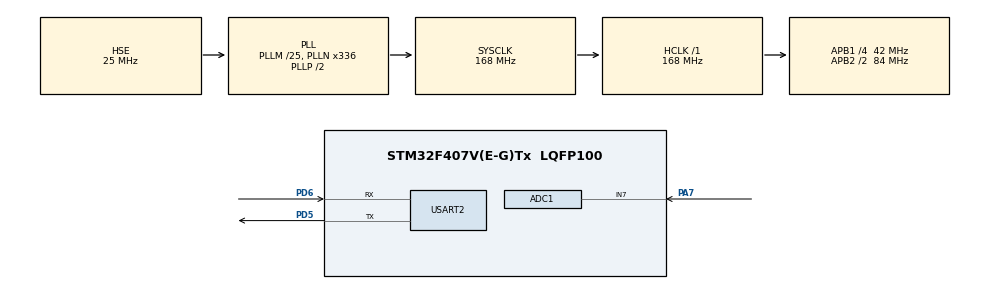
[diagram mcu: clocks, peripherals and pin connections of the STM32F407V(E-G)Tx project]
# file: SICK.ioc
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ADC1.Channel-3\#ChannelRegularConversion=ADC_CHANNEL_7
ADC1.ContinuousConvMode=ENABLE
ADC1.NbrOfConversionFlag=1
ADC1.Rank-3\#ChannelRegularConversion=1
ADC1.SamplingTime-3\#ChannelRegularConversion=ADC_SAMPLETIME_3CYCLES
ADC1.ScanConvMode=ENABLE
ADC1.master=1
Dma.ADC1.0.Direction=DMA_PERIPH_TO_MEMORY
Dma.ADC1.0.FIFOMode=DMA_FIFOMODE_DISABLE
Dma.ADC1.0.Instance=DMA2_Stream0
Dma.ADC1.0.MemDataAlignment=DMA_MDATAALIGN_WORD
Dma.ADC1.0.MemInc=DMA_MINC_ENABLE
Dma.ADC1.0.Mode=DMA_CIRCULAR
Dma.ADC1.0.PeriphDataAlignment=DMA_PDATAALIGN_WORD
Dma.ADC1.0.PeriphInc=DMA_PINC_DISABLE
Dma.ADC1.0.Priority=DMA_PRIORITY_LOW
Dma.Request0=ADC1
Mcu.Family=STM32F4
Mcu.Name=STM32F407V(E-G)Tx
Mcu.Package=LQFP100
NVIC.DMA2_Stream0_IRQn=true\:0\:0\:false\:false\:true\:false\:true\:true
NVIC.PriorityGroup=NVIC_PRIORITYGROUP_4
PA7.Signal=ADCx_IN7
PD5.Mode=Asynchronous
PD5.Signal=USART2_TX
PD6.Mode=Asynchronous
PD6.Signal=USART2_RX
PH0-OSC_IN.Mode=HSE-External-Oscillator
PH0-OSC_IN.Signal=RCC_OSC_IN
PH1-OSC_OUT.Mode=HSE-External-Oscillator
PH1-OSC_OUT.Signal=RCC_OSC_OUT
ProjectManager.HeapSize=0x200
ProjectManager.StackSize=0x400
ProjectManager.TargetToolchain=Makefile
RCC.48MHZClocksFreq_Value=48000000
RCC.AHBFreq_Value=168000000
RCC.APB1CLKDivider=RCC_HCLK_DIV4
RCC.APB1Freq_Value=42000000
RCC.APB1TimFreq_Value=84000000
RCC.APB2CLKDivider=RCC_HCLK_DIV2
RCC.APB2Freq_Value=84000000
RCC.APB2TimFreq_Value=168000000
RCC.CortexFreq_Value=168000000
RCC.HCLKFreq_Value=168000000
RCC.HSE_VALUE=25000000
RCC.HSI_VALUE=16000000
RCC.LSE_VALUE=32768
RCC.PLLM=25
RCC.PLLN=336
RCC.PLLQ=7
RCC.PLLSourceVirtual=RCC_PLLSOURCE_HSE
RCC.SYSCLKFreq_VALUE=168000000
RCC.SYSCLKSource=RCC_SYSCLKSOURCE_PLLCLK
RCC.VCOOutputFreq_Value=336000000
SH.ADCx_IN7.0=ADC1_IN7,IN7
USART2.VirtualMode=VM_ASYNC
board=custom

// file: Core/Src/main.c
/* USER CODE BEGIN Header */
/**
 ******************************************************************************
 * @file           : main.c
 * @brief          : Main program body
 ******************************************************************************
 * @attention
 *
 * Copyright (c) 2025 STMicroelectronics.
 * All rights reserved.
 *
 * This software is licensed under terms that can be found in the LICENSE file
 * in the root directory of this software component.
 * If no LICENSE file comes with this software, it is provided AS-IS.
 *
 ******************************************************************************
 */
/* USER CODE END Header */
#include "main.h"
#include "adc.h"
#include "dma.h"
#include "stm32f4xx_hal_uart.h"
#include "usart.h"
#include "gpio.h"

/* USER CODE BEGIN Includes */
#include <stdio.h>
/* USER CODE END Includes */

/* USER CODE BEGIN PV */
uint32_t ADC_BUFFER[1];
/* USER CODE END PV */

void SystemClock_Config(void);

/* USER CODE BEGIN 0 */
int _write(int file, char *data, int len)
{
  for (int i = 0; i < len; ++i)
  {
    ITM_SendChar(data[i]);
  }
  return len;
}

void HAL_ADC_ConvCpltCallback(ADC_HandleTypeDef *hadc) {
  for (int i = 0; i < 1; i++)
		HAL_UART_Transmit(&huart2, (uint8_t *)ADC_BUFFER, sizeof(ADC_BUFFER[i]), 1);
}
/* USER CODE END 0 */

int main(void)
{

  /* MCU Configuration--------------------------------------------------------*/

  /* Reset of all peripherals, Initializes the Flash interface and the Systick. */
  HAL_Init();

  /* Configure the system clock */
  SystemClock_Config();

  /* Initialize all configured peripherals */
  MX_GPIO_Init();
  MX_DMA_Init();
  MX_ADC1_Init();
  MX_USART2_UART_Init();

  /* Infinite loop */
  /* USER CODE BEGIN WHILE */
  while (1) {
		HAL_ADC_Start_DMA(&hadc1, ADC_BUFFER, 1);
    HAL_Delay(40);
    /* USER CODE END WHILE */

  }
}

void SystemClock_Config(void)
{
  RCC_OscInitTypeDef RCC_OscInitStruct = {0};
  RCC_ClkInitTypeDef RCC_ClkInitStruct = {0};

  /** Configure the main internal regulator output voltage
  */
  __HAL_RCC_PWR_CLK_ENABLE();
  __HAL_PWR_VOLTAGESCALING_CONFIG(PWR_REGULATOR_VOLTAGE_SCALE1);

  /** Initializes the RCC Oscillators according to the specified parameters
  * in the RCC_OscInitTypeDef structure.
  */
  RCC_OscInitStruct.OscillatorType = RCC_OSCILLATORTYPE_HSE;
  RCC_OscInitStruct.HSEState = RCC_HSE_ON;
  RCC_OscInitStruct.PLL.PLLState = RCC_PLL_ON;
  RCC_OscInitStruct.PLL.PLLSource = RCC_PLLSOURCE_HSE;
  RCC_OscInitStruct.PLL.PLLM = 25;
  RCC_OscInitStruct.PLL.PLLN = 336;
  RCC_OscInitStruct.PLL.PLLP = RCC_PLLP_DIV2;
  RCC_OscInitStruct.PLL.PLLQ = 7;
  if (HAL_RCC_OscConfig(&RCC_OscInitStruct) != HAL_OK)
  {
    Error_Handler();
  }

  /** Initializes the CPU, AHB and APB buses clocks
  */
  RCC_ClkInitStruct.ClockType = RCC_CLOCKTYPE_HCLK|RCC_CLOCKTYPE_SYSCLK
                              |RCC_CLOCKTYPE_PCLK1|RCC_CLOCKTYPE_PCLK2;
  RCC_ClkInitStruct.SYSCLKSource = RCC_SYSCLKSOURCE_PLLCLK;
  RCC_ClkInitStruct.AHBCLKDivider = RCC_SYSCLK_DIV1;
  RCC_ClkInitStruct.APB1CLKDivider = RCC_HCLK_DIV4;
  RCC_ClkInitStruct.APB2CLKDivider = RCC_HCLK_DIV2;

  if (HAL_RCC_ClockConfig(&RCC_ClkInitStruct, FLASH_LATENCY_5) != HAL_OK)
  {
    Error_Handler();
  }
}

void Error_Handler(void)
{
  __disable_irq();
  while (1) {
  }
}

#ifdef  USE_FULL_ASSERT
/**
  * @brief  Reports the name of the source file and the source line number
  *         where the assert_param error has occurred.
  * @param  file: pointer to the source file name
  * @param  line: assert_param error line source number
  * @retval None
  */
void assert_failed(uint8_t *file, uint32_t line)
{
  /* USER CODE BEGIN 6 */
  /* User can add his own implementation to report the file name and line
     number, ex: printf("Wrong parameters value: file %s on line %d\r\n", file,
     line) */
  /* USER CODE END 6 */
}
#endif /* USE_FULL_ASSERT */
